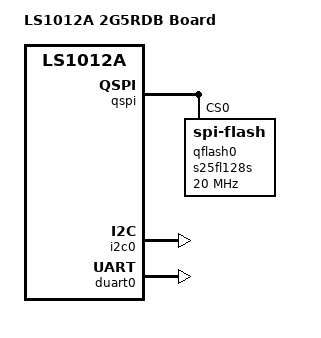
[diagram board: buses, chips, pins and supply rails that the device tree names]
/*
 * NXP ls1012a 2G5RDB board device tree source
 *
 * Copyright 2017 NXP
 *
 * SPDX-License-Identifier:	GPL-2.0+
 */

/dts-v1/;
#include "fsl-ls1012a.dtsi"

/ {
	model = "LS1012A 2G5RDB Board";

	aliases {
		spi0 = &qspi;
	};

	chosen {
		stdout-path = &duart0;
	};
};

&qspi {
	bus-num = <0>;
	status = "okay";

	qflash0: s25fl128s@0 {
		#address-cells = <1>;
		#size-cells = <1>;
		compatible = "spi-flash";
		spi-max-frequency = <20000000>;
		reg = <0>;
	};
};

&i2c0 {
	status = "okay";
};

&duart0 {
	status = "okay";
};
